# AE822FA0E5597LS0_CM55_HP_View register map
Vendor: Alif Semiconductor; Series: E8; File version: 1.0
CPU: CM55 r1p0, selectable endian, MPU, FPU, double-precision FPU, DSP, VTOR, 8 interrupt priority bits, 1 SAU regions
Registers are 32-bit, read-write, reset 0x0 unless marked. A register's access mark holds for its fields unless they carry their own. Offsets are from the block's base; [hi:lo] are bit positions.

## REFCLK_CNTControl
Base 0x1A200000
Same registers: S32K_CNTControl 0x1A400000
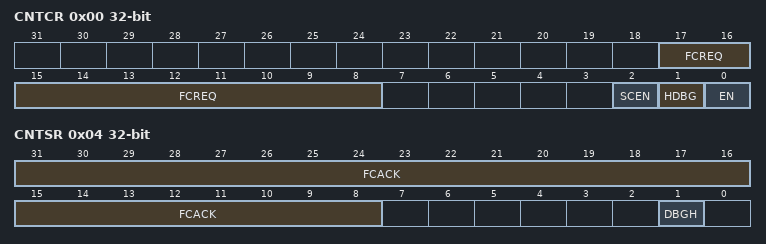
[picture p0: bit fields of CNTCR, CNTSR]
0x00 CNTCR (reset mask 0xFFFFFFF9) — Counter Control Register
  [17:8] FCREQ — Frequency change request. Specifies the index of the CNTFIDn register that holds the counter new frequency. Changing the value of this field requests a change to the counter update frequency. Any non-required most-significant bits are read-only and reserved.
  [2] SCEN — Scale Enable. This bit can only be changed when the counter is disabled (when CNTCR[EN] = 0x0). If the value of CNTCR[SCEN] changes when CNTCR[EN] = 0x1 then the counter value becomes unknown and remains unknown on future ticks of the clock.
    0=Scaling disabled. The counter value is incremented by 0x1 for each counter tick.; 1=Scaling enabled. The counter value is incremented by CNTSCR[SCALEVAL] for each counter tick.
  [1] HDBG — Halt-on-debug. Controls whether a halt-on-debug request halts the system counter.
    0=The counter ignores the halt-on-debug request; 1=When the halt-on-debug request is activated the counter halts
  [0] EN — Counter enable.
    0=System counter disabled; 1=System counter enabled
0x04 CNTSR ro (reset mask 0xFFFFFFFD) — Counter Status Register
  [31:8] FCACK — Frequency change acknowledge. Specifies the index of the CNTFIDn register that holds the counter new frequency.
  [1] DBGH — Indicates whether the counter is halted because of a halt-on-debug request.
    0=Counter is not halted; 1=Counter is halted
0x08 CNTCVL reset not defined — Counter Count Value Low Register
  [31:0] COUNTVALUE_LO — Bits [31:0] of the current counter value.
0x0C CNTCVH reset not defined — Counter Count Value High Register
  [31:0] COUNTVALUE_HI — Bits [63:32] of the current counter value.

## REFCLK_CNTRead
Base 0x1A210000
Same registers: S32K_CNTRead 0x1A410000
0x00 CNTCVL ro reset not defined — Read-only Version of CNTCVL Register
  [31:0] COUNTVALUE_LO — Read-only version of CNTCVL register.
0x04 CNTCVH ro reset not defined — Read-only Version of CNTCVH Register
  [31:0] COUNTVALUE_HI — Read-only version of CNTCVH register

## WDT_AP_CTRL
Base 0x1A300000
Same registers: WDT_AP_REFRESH 0x1A310000, WDT_AP_S_CTRL 0x1A320000, WDT_AP_S_REFRESH 0x1A330000
0x00 WDT_WRR wo — Watchdog Refresh Register
  [31:0] WRR — A write to this register causes the watchdog to refresh and start a new watch period. A read has no effect and returns 0.
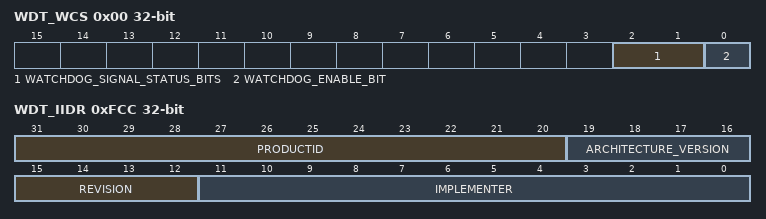
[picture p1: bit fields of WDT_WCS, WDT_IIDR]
0x00 WDT_WCS (alternate view of WDT_WRR) — Watchdog Control and Status Register
  [2:1] WATCHDOG_SIGNAL_STATUS_BITS ro — A read of this bit field indicates the current state of the watchdog signals. A write to these bits has no effect. Bit [2] reflects the status of WDT_AP_IRQ1 and bit [1] reflects the status of WDT_AP_IRQ0.
  [0] WATCHDOG_ENABLE_BIT — A read of this bit indicates the current enabled or disabled state of the watchdog. This bit resets to 0 on watchdog cold reset.
    0=The watchdog is disabled; 1=The watchdog is enabled
0x08 WDT_WOR — Watchdog Offset Register
  [31:0] WOR — 32-bit unsigned watchdog countdown timer value.
0x10 WDT_WCV_31_0 — Watchdog Compare Value Register, lower bits
  [31:0] WCV_31_0 — The lower 32 bits of the current watchdog compare value.
0x14 WDT_WCV_63_32 — Watchdog Compare Value Register, upper bits
  [31:0] WCV_63_32 — The upper 32 bits of the current watchdog compare value.
0xFCC WDT_IIDR ro — Interface Identification Register
  [31:20] PRODUCTID — Implementation defined product identifier
  [19:16] ARCHITECTURE_VERSION — WDT architecture version
  [15:12] REVISION — Implementation defined component revision number
  [11:0] IMPLEMENTER — Implementer JEP106 code
